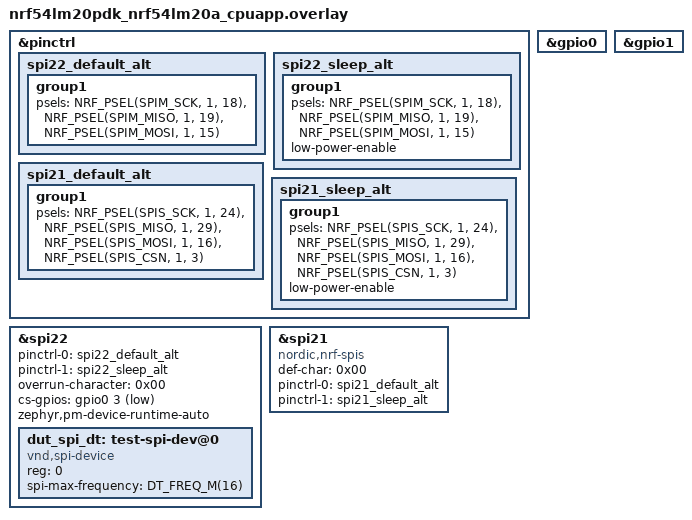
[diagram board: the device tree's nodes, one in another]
/*
 * Copyright (c) 2025 Nordic Semiconductor ASA
 *
 * SPDX-License-Identifier: LicenseRef-Nordic-5-Clause
 */

/* Test requires following loopbacks:
 * SCK:  P1.18 - P1.24
 * MISO: P1.19 - P1.29
 * MOSI: P1.15 - P1.16
 * CS:   P0.03 - P1.03
 */

&pinctrl {
	spi22_default_alt: spi22_default_alt {
		group1 {
			psels = <NRF_PSEL(SPIM_SCK, 1, 18)>,
				<NRF_PSEL(SPIM_MISO, 1, 19)>,
				<NRF_PSEL(SPIM_MOSI, 1, 15)>;
		};
	};

	spi22_sleep_alt: spi22_sleep_alt {
		group1 {
			psels = <NRF_PSEL(SPIM_SCK, 1, 18)>,
				<NRF_PSEL(SPIM_MISO, 1, 19)>,
				<NRF_PSEL(SPIM_MOSI, 1, 15)>;
			low-power-enable;
		};
	};

	spi21_default_alt: spi21_default_alt {
		group1 {
			psels = <NRF_PSEL(SPIS_SCK, 1, 24)>,
				<NRF_PSEL(SPIS_MISO, 1, 29)>,
				<NRF_PSEL(SPIS_MOSI, 1, 16)>,
				<NRF_PSEL(SPIS_CSN, 1, 3)>;
		};
	};

	spi21_sleep_alt: spi21_sleep_alt {
		group1 {
			psels = <NRF_PSEL(SPIS_SCK, 1, 24)>,
				<NRF_PSEL(SPIS_MISO, 1, 29)>,
				<NRF_PSEL(SPIS_MOSI, 1, 16)>,
				<NRF_PSEL(SPIS_CSN, 1, 3)>;
			low-power-enable;
		};
	};
};


&gpio0 {
	status = "okay";
};

&gpio1 {
	status = "okay";
};

&spi22 {
	status = "okay";
	pinctrl-0 = <&spi22_default_alt>;
	pinctrl-1 = <&spi22_sleep_alt>;
	pinctrl-names = "default", "sleep";
	overrun-character = <0x00>;
	cs-gpios = <&gpio0 3 GPIO_ACTIVE_LOW>;
	zephyr,pm-device-runtime-auto;
	dut_spi_dt: test-spi-dev@0 {
		compatible = "vnd,spi-device";
		reg = <0>;
		spi-max-frequency = <DT_FREQ_M(16)>;
	};
};

dut_spis: &spi21 {
	compatible = "nordic,nrf-spis";
	status = "okay";
	def-char = <0x00>;
	pinctrl-0 = <&spi21_default_alt>;
	pinctrl-1 = <&spi21_sleep_alt>;
	pinctrl-names = "default", "sleep";
	/delete-property/rx-delay-supported;
	/delete-property/rx-delay;
};
